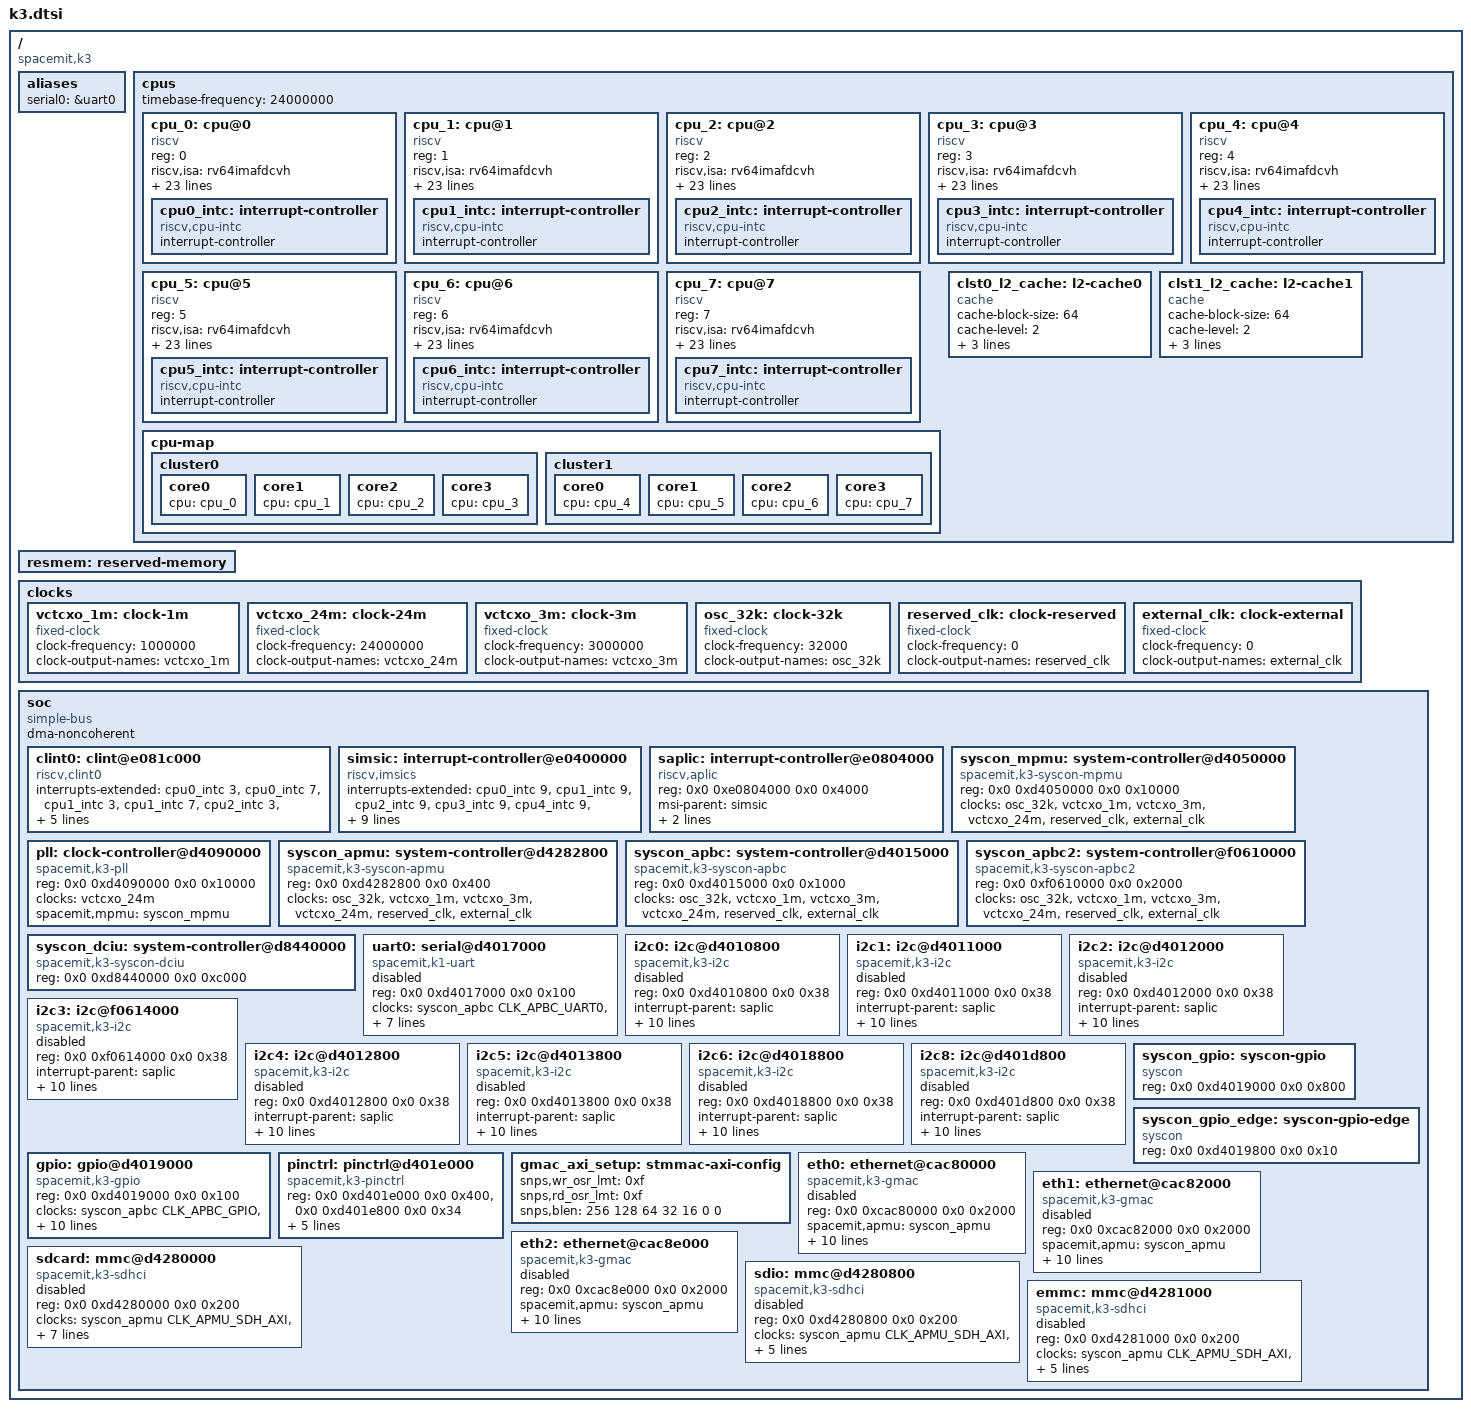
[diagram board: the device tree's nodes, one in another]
// SPDX-License-Identifier: (GPL-2.0 OR MIT)
/* Copyright (c) 2025 Spacemit, Inc */

/dts-v1/;

#include <dt-bindings/clock/spacemit,k3-syscon.h>
#include <dt-bindings/interrupt-controller/irq.h>

/ {
	compatible = "spacemit,k3";
	#address-cells = <2>;
	#size-cells = <2>;

	aliases {
		serial0 = &uart0;
	};

	cpus: cpus {
		#address-cells = <1>;
		#size-cells = <0>;
		timebase-frequency = <24000000>;

		cpu_0: cpu@0 {
			device_type = "cpu";
			reg = <0>;
			status = "okay";
			compatible = "riscv";
			riscv,isa = "rv64imafdcvh";
			riscv,isa-base = "rv64i";
			riscv,isa-extensions = "i", "m", "a", "f", "d", "c", "v", "h",
					       "smaia", "smstateen", "ssaia", "sscofpmf",
					       "ssnpm", "sstc", "svade", "svinval",
					       "svnapot", "svpbmt", "zawrs", "zba", "zbb",
					       "zbc", "zbs", "zca", "zcb", "zcd", "zcmop",
					       "zfa", "zfbfmin", "zfh", "zfhmin", "zicbom", "zicbop",
					       "zicboz", "zicntr", "zicond", "zicsr",
					       "zifencei", "zihintntl", "zihintpause",
					       "zihpm", "zimop", "zkt", "zvbb", "zvbc",
					       "zvfbfmin", "zvfbfwma", "zvfh", "zvfhmin",
					       "zvkb", "zvkg", "zvkn", "zvknc", "zvkned",
					       "zvkng", "zvknha", "zvknhb", "zvks",
					       "zvksc", "zvksed", "zvksg", "zvksh", "zvkt";
			riscv,cbom-block-size = <64>;
			riscv,cboz-block-size = <64>;
			riscv,cbop-block-size = <64>;
			i-cache-block-size = <64>;
			i-cache-size = <65536>;
			i-cache-sets = <256>;
			d-cache-block-size = <64>;
			d-cache-size = <65536>;
			d-cache-sets = <256>;
			next-level-cache = <&clst0_l2_cache>;
			mmu-type = "riscv,sv39";
			cpu0_intc: interrupt-controller {
				#interrupt-cells = <1>;
				compatible = "riscv,cpu-intc";
				interrupt-controller;
			};
		};

		cpu_1: cpu@1 {
			device_type = "cpu";
			reg = <1>;
			status = "okay";
			compatible = "riscv";
			riscv,isa = "rv64imafdcvh";
			riscv,isa-base = "rv64i";
			riscv,isa-extensions = "i", "m", "a", "f", "d", "c", "v", "h",
					       "smaia", "smstateen", "ssaia", "sscofpmf",
					       "ssnpm", "sstc", "svade", "svinval",
					       "svnapot", "svpbmt", "zawrs", "zba", "zbb",
					       "zbc", "zbs", "zca", "zcb", "zcd", "zcmop",
					       "zfa", "zfbfmin", "zfh", "zfhmin", "zicbom", "zicbop",
					       "zicboz", "zicntr", "zicond", "zicsr",
					       "zifencei", "zihintntl", "zihintpause",
					       "zihpm", "zimop", "zkt", "zvbb", "zvbc",
					       "zvfbfmin", "zvfbfwma", "zvfh", "zvfhmin",
					       "zvkb", "zvkg", "zvkn", "zvknc", "zvkned",
					       "zvkng", "zvknha", "zvknhb", "zvks",
					       "zvksc", "zvksed", "zvksg", "zvksh", "zvkt";
			riscv,cbom-block-size = <64>;
			riscv,cboz-block-size = <64>;
			riscv,cbop-block-size = <64>;
			i-cache-block-size = <64>;
			i-cache-size = <65536>;
			i-cache-sets = <256>;
			d-cache-block-size = <64>;
			d-cache-size = <65536>;
			d-cache-sets = <256>;
			next-level-cache = <&clst0_l2_cache>;
			mmu-type = "riscv,sv39";
			cpu1_intc: interrupt-controller {
				#interrupt-cells = <1>;
				compatible = "riscv,cpu-intc";
				interrupt-controller;
			};
		};

		cpu_2: cpu@2 {
			device_type = "cpu";
			reg = <2>;
			status = "okay";
			compatible = "riscv";
			riscv,isa = "rv64imafdcvh";
			riscv,isa-base = "rv64i";
			riscv,isa-extensions = "i", "m", "a", "f", "d", "c", "v", "h",
					       "smaia", "smstateen", "ssaia", "sscofpmf",
					       "ssnpm", "sstc", "svade", "svinval",
					       "svnapot", "svpbmt", "zawrs", "zba", "zbb",
					       "zbc", "zbs", "zca", "zcb", "zcd", "zcmop",
					       "zfa", "zfbfmin", "zfh", "zfhmin", "zicbom", "zicbop",
					       "zicboz", "zicntr", "zicond", "zicsr",
					       "zifencei", "zihintntl", "zihintpause",
					       "zihpm", "zimop", "zkt", "zvbb", "zvbc",
					       "zvfbfmin", "zvfbfwma", "zvfh", "zvfhmin",
					       "zvkb", "zvkg", "zvkn", "zvknc", "zvkned",
					       "zvkng", "zvknha", "zvknhb", "zvks",
					       "zvksc", "zvksed", "zvksg", "zvksh", "zvkt";
			riscv,cbom-block-size = <64>;
			riscv,cboz-block-size = <64>;
			riscv,cbop-block-size = <64>;
			i-cache-block-size = <64>;
			i-cache-size = <65536>;
			i-cache-sets = <256>;
			d-cache-block-size = <64>;
			d-cache-size = <65536>;
			d-cache-sets = <256>;
			next-level-cache = <&clst0_l2_cache>;
			mmu-type = "riscv,sv39";
			cpu2_intc: interrupt-controller {
				#interrupt-cells = <1>;
				compatible = "riscv,cpu-intc";
				interrupt-controller;
			};
		};

		cpu_3: cpu@3 {
			device_type = "cpu";
			reg = <3>;
			status = "okay";
			compatible = "riscv";
			riscv,isa = "rv64imafdcvh";
			riscv,isa-base = "rv64i";
			riscv,isa-extensions = "i", "m", "a", "f", "d", "c", "v", "h",
					       "smaia", "smstateen", "ssaia", "sscofpmf",
					       "ssnpm", "sstc", "svade", "svinval",
					       "svnapot", "svpbmt", "zawrs", "zba", "zbb",
					       "zbc", "zbs", "zca", "zcb", "zcd", "zcmop",
					       "zfa", "zfbfmin", "zfh", "zfhmin", "zicbom", "zicbop",
					       "zicboz", "zicntr", "zicond", "zicsr",
					       "zifencei", "zihintntl", "zihintpause",
					       "zihpm", "zimop", "zkt", "zvbb", "zvbc",
					       "zvfbfmin", "zvfbfwma", "zvfh", "zvfhmin",
					       "zvkb", "zvkg", "zvkn", "zvknc", "zvkned",
					       "zvkng", "zvknha", "zvknhb", "zvks",
					       "zvksc", "zvksed", "zvksg", "zvksh", "zvkt";
			riscv,cbom-block-size = <64>;
			riscv,cboz-block-size = <64>;
			riscv,cbop-block-size = <64>;
			i-cache-block-size = <64>;
			i-cache-size = <65536>;
			i-cache-sets = <256>;
			d-cache-block-size = <64>;
			d-cache-size = <65536>;
			d-cache-sets = <256>;
			next-level-cache = <&clst0_l2_cache>;
			mmu-type = "riscv,sv39";
			cpu3_intc: interrupt-controller {
				#interrupt-cells = <1>;
				compatible = "riscv,cpu-intc";
				interrupt-controller;
			};
		};

		cpu_4: cpu@4 {
			device_type = "cpu";
			reg = <4>;
			status = "okay";
			compatible = "riscv";
			riscv,isa = "rv64imafdcvh";
			riscv,isa-base = "rv64i";
			riscv,isa-extensions = "i", "m", "a", "f", "d", "c", "v", "h",
					       "smaia", "smstateen", "ssaia", "sscofpmf",
					       "ssnpm", "sstc", "svade", "svinval",
					       "svnapot", "svpbmt", "zawrs", "zba", "zbb",
					       "zbc", "zbs", "zca", "zcb", "zcd", "zcmop",
					       "zfa", "zfbfmin", "zfh", "zfhmin", "zicbom", "zicbop",
					       "zicboz", "zicntr", "zicond", "zicsr",
					       "zifencei", "zihintntl", "zihintpause",
					       "zihpm", "zimop", "zkt", "zvbb", "zvbc",
					       "zvfbfmin", "zvfbfwma", "zvfh", "zvfhmin",
					       "zvkb", "zvkg", "zvkn", "zvknc", "zvkned",
					       "zvkng", "zvknha", "zvknhb", "zvks",
					       "zvksc", "zvksed", "zvksg", "zvksh", "zvkt";
			riscv,cbom-block-size = <64>;
			riscv,cboz-block-size = <64>;
			riscv,cbop-block-size = <64>;
			i-cache-block-size = <64>;
			i-cache-size = <65536>;
			i-cache-sets = <256>;
			d-cache-block-size = <64>;
			d-cache-size = <65536>;
			d-cache-sets = <256>;
			next-level-cache = <&clst1_l2_cache>;
			mmu-type = "riscv,sv39";
			cpu4_intc: interrupt-controller {
				#interrupt-cells = <1>;
				compatible = "riscv,cpu-intc";
				interrupt-controller;
			};
		};

		cpu_5: cpu@5 {
			device_type = "cpu";
			reg = <5>;
			status = "okay";
			compatible = "riscv";
			riscv,isa = "rv64imafdcvh";
			riscv,isa-base = "rv64i";
			riscv,isa-extensions = "i", "m", "a", "f", "d", "c", "v", "h",
					       "smaia", "smstateen", "ssaia", "sscofpmf",
					       "ssnpm", "sstc", "svade", "svinval",
					       "svnapot", "svpbmt", "zawrs", "zba", "zbb",
					       "zbc", "zbs", "zca", "zcb", "zcd", "zcmop",
					       "zfa", "zfbfmin", "zfh", "zfhmin", "zicbom", "zicbop",
					       "zicboz", "zicntr", "zicond", "zicsr",
					       "zifencei", "zihintntl", "zihintpause",
					       "zihpm", "zimop", "zkt", "zvbb", "zvbc",
					       "zvfbfmin", "zvfbfwma", "zvfh", "zvfhmin",
					       "zvkb", "zvkg", "zvkn", "zvknc", "zvkned",
					       "zvkng", "zvknha", "zvknhb", "zvks",
					       "zvksc", "zvksed", "zvksg", "zvksh", "zvkt";
			riscv,cbom-block-size = <64>;
			riscv,cboz-block-size = <64>;
			riscv,cbop-block-size = <64>;
			i-cache-block-size = <64>;
			i-cache-size = <65536>;
			i-cache-sets = <256>;
			d-cache-block-size = <64>;
			d-cache-size = <65536>;
			d-cache-sets = <256>;
			next-level-cache = <&clst1_l2_cache>;
			mmu-type = "riscv,sv39";
			cpu5_intc: interrupt-controller {
				#interrupt-cells = <1>;
				compatible = "riscv,cpu-intc";
				interrupt-controller;
			};
		};

		cpu_6: cpu@6 {
			device_type = "cpu";
			reg = <6>;
			status = "okay";
			compatible = "riscv";
			riscv,isa = "rv64imafdcvh";
			riscv,isa-base = "rv64i";
			riscv,isa-extensions = "i", "m", "a", "f", "d", "c", "v", "h",
					       "smaia", "smstateen", "ssaia", "sscofpmf",
					       "ssnpm", "sstc", "svade", "svinval",
					       "svnapot", "svpbmt", "zawrs", "zba", "zbb",
					       "zbc", "zbs", "zca", "zcb", "zcd", "zcmop",
					       "zfa", "zfbfmin", "zfh", "zfhmin", "zicbom", "zicbop",
					       "zicboz", "zicntr", "zicond", "zicsr",
					       "zifencei", "zihintntl", "zihintpause",
					       "zihpm", "zimop", "zkt", "zvbb", "zvbc",
					       "zvfbfmin", "zvfbfwma", "zvfh", "zvfhmin",
					       "zvkb", "zvkg", "zvkn", "zvknc", "zvkned",
					       "zvkng", "zvknha", "zvknhb", "zvks",
					       "zvksc", "zvksed", "zvksg", "zvksh", "zvkt";
			riscv,cbom-block-size = <64>;
			riscv,cboz-block-size = <64>;
			riscv,cbop-block-size = <64>;
			i-cache-block-size = <64>;
			i-cache-size = <65536>;
			i-cache-sets = <256>;
			d-cache-block-size = <64>;
			d-cache-size = <65536>;
			d-cache-sets = <256>;
			next-level-cache = <&clst1_l2_cache>;
			mmu-type = "riscv,sv39";
			cpu6_intc: interrupt-controller {
				#interrupt-cells = <1>;
				compatible = "riscv,cpu-intc";
				interrupt-controller;
			};
		};

		cpu_7: cpu@7 {
			device_type = "cpu";
			reg = <7>;
			status = "okay";
			compatible = "riscv";
			riscv,isa = "rv64imafdcvh";
			riscv,isa-base = "rv64i";
			riscv,isa-extensions = "i", "m", "a", "f", "d", "c", "v", "h",
					       "smaia", "smstateen", "ssaia", "sscofpmf",
					       "ssnpm", "sstc", "svade", "svinval",
					       "svnapot", "svpbmt", "zawrs", "zba", "zbb",
					       "zbc", "zbs", "zca", "zcb", "zcd", "zcmop",
					       "zfa", "zfbfmin", "zfh", "zfhmin", "zicbom", "zicbop",
					       "zicboz", "zicntr", "zicond", "zicsr",
					       "zifencei", "zihintntl", "zihintpause",
					       "zihpm", "zimop", "zkt", "zvbb", "zvbc",
					       "zvfbfmin", "zvfbfwma", "zvfh", "zvfhmin",
					       "zvkb", "zvkg", "zvkn", "zvknc", "zvkned",
					       "zvkng", "zvknha", "zvknhb", "zvks",
					       "zvksc", "zvksed", "zvksg", "zvksh", "zvkt";
			riscv,cbom-block-size = <64>;
			riscv,cboz-block-size = <64>;
			riscv,cbop-block-size = <64>;
			i-cache-block-size = <64>;
			i-cache-size = <65536>;
			i-cache-sets = <256>;
			d-cache-block-size = <64>;
			d-cache-size = <65536>;
			d-cache-sets = <256>;
			next-level-cache = <&clst1_l2_cache>;
			mmu-type = "riscv,sv39";
			cpu7_intc: interrupt-controller {
				#interrupt-cells = <1>;
				compatible = "riscv,cpu-intc";
				interrupt-controller;
			};
		};

		cpu-map {
			cluster0 {
				core0 {
					cpu = <&cpu_0>;
				};

				core1 {
					cpu = <&cpu_1>;
				};

				core2 {
					cpu = <&cpu_2>;
				};

				core3 {
					cpu = <&cpu_3>;
				};
			};
			cluster1 {
				core0 {
					cpu = <&cpu_4>;
				};

				core1 {
					cpu = <&cpu_5>;
				};

				core2 {
					cpu = <&cpu_6>;
				};

				core3 {
					cpu = <&cpu_7>;
				};
			};
		};

		clst0_l2_cache: l2-cache0 {
			compatible = "cache";
			cache-block-size = <64>;
			cache-level = <2>;
			cache-size = <4194304>;
			cache-sets = <4096>;
			cache-unified;
		};

		clst1_l2_cache: l2-cache1 {
			compatible = "cache";
			cache-block-size = <64>;
			cache-level = <2>;
			cache-size = <4194304>;
			cache-sets = <4096>;
			cache-unified;
		};
	};

	resmem: reserved-memory {
		#address-cells = <2>;
		#size-cells = <2>;
		ranges;
	};

	clocks {
		vctcxo_1m: clock-1m {
			compatible = "fixed-clock";
			clock-frequency = <1000000>;
			clock-output-names = "vctcxo_1m";
			#clock-cells = <0>;
		};

		vctcxo_24m: clock-24m {
			compatible = "fixed-clock";
			clock-frequency = <24000000>;
			clock-output-names = "vctcxo_24m";
			#clock-cells = <0>;
		};

		vctcxo_3m: clock-3m {
			compatible = "fixed-clock";
			clock-frequency = <3000000>;
			clock-output-names = "vctcxo_3m";
			#clock-cells = <0>;
		};

		osc_32k: clock-32k {
			compatible = "fixed-clock";
			clock-frequency = <32000>;
			clock-output-names = "osc_32k";
			#clock-cells = <0>;
		};

		reserved_clk: clock-reserved {
			compatible = "fixed-clock";
			clock-frequency = <0>;
			clock-output-names = "reserved_clk";
			#clock-cells = <0>;
		};

		external_clk: clock-external {
			compatible = "fixed-clock";
			clock-frequency = <0>;
			clock-output-names = "external_clk";
			#clock-cells = <0>;
		};
	};

	soc: soc {
		#address-cells = <2>;
		#size-cells = <2>;
		compatible = "simple-bus";
		dma-noncoherent;
		ranges;

		clint0: clint@e081c000 {
			compatible = "riscv,clint0";
			interrupts-extended = <
				&cpu0_intc  3 &cpu0_intc  7
				&cpu1_intc  3 &cpu1_intc  7
				&cpu2_intc  3 &cpu2_intc  7
				&cpu3_intc  3 &cpu3_intc  7
				&cpu4_intc  3 &cpu4_intc  7
				&cpu5_intc  3 &cpu5_intc  7
				&cpu6_intc  3 &cpu6_intc  7
				&cpu7_intc  3 &cpu7_intc  7>;
			reg = <0x0 0xe081c000 0x0 0x0004000>;
		};

		simsic: interrupt-controller@e0400000 {
			compatible = "riscv,imsics";
			interrupts-extended = <
				&cpu0_intc 9 &cpu1_intc 9
				&cpu2_intc 9 &cpu3_intc 9
				&cpu4_intc 9 &cpu5_intc 9
				&cpu6_intc 9 &cpu7_intc 9>;

			reg = <0x0 0xe0400000 0x0 0x40000
				0x0 0xe0440000 0x0 0x40000
				0x0 0xe0480000 0x0 0x40000
				0x0 0xe04c0000 0x0 0x40000
				0x0 0xe0500000 0x0 0x40000
				0x0 0xe0540000 0x0 0x40000
				0x0 0xe0580000 0x0 0x40000
				0x0 0xe05c0000 0x0 0x40000>;
			interrupt-controller;
			#interrupt-cells = <0>;
			#msi-cells = <0>;
			msi-controller;
			/* Number of interrupt identities: 511 */
			riscv,num-ids = <511>;
			/* Number of guest interrupt identities: 511 */
			riscv,num-guest-ids = <511>;
			/* Number of HART index bits: 4 (2^4 = 16 harts) */
			riscv,hart-index-bits = <4>;
			riscv,guest-index-bits = <6>;
			status = "okay";
		};

		saplic: interrupt-controller@e0804000 {
			compatible = "riscv,aplic";
			/* aplic config */
			reg = <0x0 0xe0804000 0x0 0x4000>;
			msi-parent = <&simsic>;
			#interrupt-cells = <2>;
			interrupt-controller;
			/* the number of wired interrupt sources:512 */
			riscv,num-sources = <512>;
			status = "okay";
		};

		syscon_mpmu: system-controller@d4050000 {
			compatible = "spacemit,k3-syscon-mpmu", "syscon";
			reg = <0x0 0xd4050000 0x0 0x10000>;
			clocks = <&osc_32k>, <&vctcxo_1m>, <&vctcxo_3m>,
				 <&vctcxo_24m>, <&reserved_clk>, <&external_clk>;
			clock-names = "osc_32k", "vctcxo_1m", "vctcxo_3m", "vctcxo_24m",
				      "reserved_clk", "external_clk";
			#clock-cells = <1>;
			#reset-cells = <1>;
		};

		pll: clock-controller@d4090000 {
			compatible = "spacemit,k3-pll";
			reg = <0x0 0xd4090000 0x0 0x10000>;
			clocks = <&vctcxo_24m>;
			spacemit,mpmu = <&syscon_mpmu>;
			#clock-cells = <1>;
		};

		syscon_apmu: system-controller@d4282800 {
			compatible = "spacemit,k3-syscon-apmu", "syscon";
			reg = <0x0 0xd4282800 0x0 0x400>;
			clocks = <&osc_32k>, <&vctcxo_1m>, <&vctcxo_3m>, <&vctcxo_24m>,
				 <&reserved_clk>, <&external_clk>;
			clock-names = "osc_32k", "vctcxo_1m", "vctcxo_3m", "vctcxo_24m",
				      "reserved_clk", "external_clk";
			#clock-cells = <1>;
			#power-domain-cells = <1>;
			#reset-cells = <1>;
		};

		syscon_apbc: system-controller@d4015000 {
			compatible = "spacemit,k3-syscon-apbc", "syscon";
			reg = <0x0 0xd4015000 0x0 0x1000>;
			clocks = <&osc_32k>, <&vctcxo_1m>, <&vctcxo_3m>, <&vctcxo_24m>,
				 <&reserved_clk>, <&external_clk>;
			clock-names = "osc_32k", "vctcxo_1m", "vctcxo_3m", "vctcxo_24m",
				      "reserved_clk", "external_clk";
			#clock-cells = <1>;
			#reset-cells = <1>;
		};

		syscon_apbc2: system-controller@f0610000 {
			compatible = "spacemit,k3-syscon-apbc2", "syscon";
			reg = <0x0 0xf0610000 0x0 0x2000>;
			clocks = <&osc_32k>, <&vctcxo_1m>, <&vctcxo_3m>, <&vctcxo_24m>,
				 <&reserved_clk>, <&external_clk>;
			clock-names = "osc_32k", "vctcxo_1m", "vctcxo_3m", "vctcxo_24m",
				      "reserved_clk", "external_clk";
			#clock-cells = <1>;
			#reset-cells = <1>;
		};

		syscon_dciu: system-controller@d8440000 {
			compatible = "spacemit,k3-syscon-dciu", "syscon";
			reg = <0x0 0xd8440000 0x0 0xc000>;
			#clock-cells = <1>;
			#reset-cells = <1>;
		};

		uart0: serial@d4017000 {
			compatible = "spacemit,k1-uart",
				     "intel,xscale-uart";
			reg = <0x0 0xd4017000 0x0 0x100>;
			clocks = <&syscon_apbc CLK_APBC_UART0>,
				 <&syscon_apbc CLK_APBC_UART0_BUS>,
				 <&syscon_mpmu CLK_MPMU_SLOW_UART>;
			clock-names = "core", "bus", "gate";
			resets = <&syscon_apbc RESET_APBC_UART0>;
			reg-shift = <2>;
			reg-io-width = <4>;
			interrupt-parent = <&saplic>;
			interrupts = <42 IRQ_TYPE_LEVEL_HIGH>;
			status = "disabled";
		};

		i2c0: i2c@d4010800 {
			compatible = "spacemit,k3-i2c",
				     "spacemit,k1-i2c";
			reg = <0x0 0xd4010800 0x0 0x38>;
			#address-cells = <1>;
			#size-cells = <0>;
			interrupt-parent = <&saplic>;
			interrupts = <36 IRQ_TYPE_LEVEL_HIGH>;
			clocks = <&syscon_apbc CLK_APBC_TWSI0>,
				 <&syscon_apbc CLK_APBC_TWSI0_BUS>;
			clock-names = "func", "bus";
			resets = <&syscon_apbc RESET_APBC_TWSI0>;

			spacemit,adapter-id = <0>;
			spacemit,i2c-master-code = /bits/ 8 <0x0e>;
			spacemit,i2c-clk-rate = <32000000>;
			spacemit,i2c-lcr = <0x82c469f>;
			spacemit,i2c-wcr = <0x142a>;
			/* apb clock: 26MHz or 52MHz */
			spacemit,apb_clock = <52000000>;

			status = "disabled";
		};

		i2c1: i2c@d4011000 {
			compatible = "spacemit,k3-i2c",
				     "spacemit,k1-i2c";
			reg = <0x0 0xd4011000 0x0 0x38>;
			#address-cells = <1>;
			#size-cells = <0>;
			interrupt-parent = <&saplic>;
			interrupts = <37 IRQ_TYPE_LEVEL_HIGH>;
			clocks = <&syscon_apbc CLK_APBC_TWSI1>,
				 <&syscon_apbc CLK_APBC_TWSI1_BUS>;
			clock-names = "func", "bus";
			resets = <&syscon_apbc RESET_APBC_TWSI1>;

			spacemit,adapter-id = <1>;
			spacemit,i2c-master-code = /bits/ 8 <0x0e>;
			spacemit,i2c-clk-rate = <32000000>;
			spacemit,i2c-lcr = <0x82c469f>;
			spacemit,i2c-wcr = <0x142a>;
			/* apb clock: 26MHz or 52MHz */
			spacemit,apb_clock = <52000000>;

			status = "disabled";
		};

		i2c2: i2c@d4012000 {
			compatible = "spacemit,k3-i2c",
				     "spacemit,k1-i2c";
			reg = <0x0 0xd4012000 0x0 0x38>;
			#address-cells = <1>;
			#size-cells = <0>;
			interrupt-parent = <&saplic>;
			interrupts = <38 IRQ_TYPE_LEVEL_HIGH>;
			clocks = <&syscon_apbc CLK_APBC_TWSI2>,
				 <&syscon_apbc CLK_APBC_TWSI2_BUS>;
			clock-names = "func", "bus";
			resets = <&syscon_apbc RESET_APBC_TWSI2>;

			spacemit,adapter-id = <2>;
			spacemit,i2c-master-code = /bits/ 8 <0x0e>;
			spacemit,i2c-clk-rate = <32000000>;
			spacemit,i2c-lcr = <0x82c469f>;
			spacemit,i2c-wcr = <0x142a>;
			/* apb clock: 26MHz or 52MHz */
			spacemit,apb_clock = <52000000>;

			status = "disabled";
		};

		i2c3: i2c@f0614000 {
			compatible = "spacemit,k3-i2c",
				     "spacemit,k1-i2c";
			reg = <0x0 0xf0614000 0x0 0x38>;
			#address-cells = <1>;
			#size-cells = <0>;
			interrupt-parent = <&saplic>;
			interrupts = <39 IRQ_TYPE_LEVEL_HIGH>;
			clocks = <&syscon_apbc2 CLK_APBC2_SEC_TWSI3>,
				 <&syscon_apbc2 CLK_APBC2_SEC_TWSI3_BUS>;
			clock-names = "func", "bus";
			resets = <&syscon_apbc2 RESET_APBC2_SEC_TWSI3>;

			spacemit,adapter-id = <3>;
			spacemit,i2c-master-code = /bits/ 8 <0x0e>;
			spacemit,i2c-clk-rate = <32000000>;
			spacemit,i2c-lcr = <0x82c469f>;
			spacemit,i2c-wcr = <0x142a>;
			/* apb clock: 26MHz or 52MHz */
			spacemit,apb_clock = <52000000>;

			status = "disabled";
		};

		i2c4: i2c@d4012800 {
			compatible = "spacemit,k3-i2c",
				     "spacemit,k1-i2c";
			reg = <0x0 0xd4012800 0x0 0x38>;
			#address-cells = <1>;
			#size-cells = <0>;
			interrupt-parent = <&saplic>;
			interrupts = <40 IRQ_TYPE_LEVEL_HIGH>;
			clocks = <&syscon_apbc CLK_APBC_TWSI4>,
				 <&syscon_apbc CLK_APBC_TWSI4_BUS>;
			clock-names = "func", "bus";
			resets = <&syscon_apbc RESET_APBC_TWSI4>;

			spacemit,adapter-id = <4>;
			spacemit,i2c-master-code = /bits/ 8 <0x0e>;
			spacemit,i2c-clk-rate = <32000000>;
			spacemit,i2c-lcr = <0x82c469f>;
			spacemit,i2c-wcr = <0x142a>;
			/* apb clock: 26MHz or 52MHz */
			spacemit,apb_clock = <52000000>;

			status = "disabled";
		};

		i2c5: i2c@d4013800 {
			compatible = "spacemit,k3-i2c",
				     "spacemit,k1-i2c";
			reg = <0x0 0xd4013800 0x0 0x38>;
			#address-cells = <1>;
			#size-cells = <0>;
			interrupt-parent = <&saplic>;
			interrupts = <41 IRQ_TYPE_LEVEL_HIGH>;
			clocks = <&syscon_apbc CLK_APBC_TWSI5>,
				 <&syscon_apbc CLK_APBC_TWSI5_BUS>;
			clock-names = "func", "bus";
			resets = <&syscon_apbc RESET_APBC_TWSI5>;

			spacemit,adapter-id = <5>;
			spacemit,i2c-master-code = /bits/ 8 <0x0e>;
			spacemit,i2c-clk-rate = <32000000>;
			spacemit,i2c-lcr = <0x82c469f>;
			spacemit,i2c-wcr = <0x142a>;
			/* apb clock: 26MHz or 52MHz */
			spacemit,apb_clock = <52000000>;

			status = "disabled";
		};

		i2c6: i2c@d4018800 {
			compatible = "spacemit,k3-i2c",
				     "spacemit,k1-i2c";
			reg = <0x0 0xd4018800 0x0 0x38>;
			#address-cells = <1>;
			#size-cells = <0>;
			interrupt-parent = <&saplic>;
			interrupts = <70 IRQ_TYPE_LEVEL_HIGH>;
			clocks = <&syscon_apbc CLK_APBC_TWSI6>,
				 <&syscon_apbc CLK_APBC_TWSI6_BUS>;
			clock-names = "func", "bus";
			resets = <&syscon_apbc RESET_APBC_TWSI6>;

			spacemit,adapter-id = <6>;
			spacemit,i2c-master-code = /bits/ 8 <0x0e>;
			spacemit,i2c-clk-rate = <32000000>;
			spacemit,i2c-lcr = <0x82c469f>;
			spacemit,i2c-wcr = <0x142a>;
			/* apb clock: 26MHz or 52MHz */
			spacemit,apb_clock = <52000000>;

			status = "disabled";
		};

		i2c8: i2c@d401d800 {
			compatible = "spacemit,k3-i2c",
				     "spacemit,k1-i2c";
			reg = <0x0 0xd401d800 0x0 0x38>;
			#address-cells = <1>;
			#size-cells = <0>;
			interrupt-parent = <&saplic>;
			interrupts = <19 IRQ_TYPE_LEVEL_HIGH>;
			clocks = <&syscon_apbc CLK_APBC_TWSI8>,
				 <&syscon_apbc CLK_APBC_TWSI8_BUS>;
			clock-names = "func", "bus";
			resets = <&syscon_apbc RESET_APBC_TWSI8>;

			spacemit,adapter-id = <8>;
			spacemit,i2c-master-code = /bits/ 8 <0x0e>;
			spacemit,i2c-clk-rate = <32000000>;
			spacemit,i2c-lcr = <0x82c469f>;
			spacemit,i2c-wcr = <0x142a>;
			/* apb clock: 26MHz or 52MHz */
			spacemit,apb_clock = <52000000>;

			status = "disabled";
		};

		syscon_gpio: syscon-gpio{
			compatible = "syscon";
			reg = <0x0 0xd4019000 0x0 0x800>;
		};

		syscon_gpio_edge: syscon-gpio-edge{
			compatible = "syscon";
			reg = <0x0 0xd4019800 0x0 0x10>;
		};

		gpio: gpio@d4019000 {
			compatible = "spacemit,k3-gpio";
			reg = <0x0 0xd4019000 0x0 0x100>;
			clocks = <&syscon_apbc CLK_APBC_GPIO>,
				 <&syscon_apbc CLK_APBC_GPIO_BUS>;
			clock-names = "core", "bus";
			gpio-controller;
			#gpio-cells = <3>;
			interrupts = <58 IRQ_TYPE_LEVEL_HIGH>;
			interrupt-parent = <&saplic>;
			interrupt-controller;
			#interrupt-cells = <3>;
			syscon = <&syscon_gpio>;
			syscon-edge = <&syscon_gpio_edge>;
			gpio-ranges = <&pinctrl 0 0 0 32>,
				      <&pinctrl 1 0 32 32>,
				      <&pinctrl 2 0 64 32>,
				      <&pinctrl 3 0 96 32>;
		};

		pinctrl: pinctrl@d401e000 {
			compatible = "spacemit,k3-pinctrl";
			reg = <0x0 0xd401e000 0x0 0x400>,
			      <0x0 0xd401e800 0x0 0x34>;
			clocks = <&syscon_apbc CLK_APBC_AIB>,
				 <&syscon_apbc CLK_APBC_AIB_BUS>;
			clock-names = "func", "bus";
			syscon = <&syscon_gpio>;
			syscon-edge = <&syscon_gpio_edge>;
			spacemit,apbc = <&syscon_apbc 0x50>;
		};

		gmac_axi_setup: stmmac-axi-config {
			snps,wr_osr_lmt = <0xf>;
			snps,rd_osr_lmt = <0xf>;
			/* max axi burst len is 256 */
			snps,blen = <256 128 64 32 16 0 0>;
		};

		eth0: ethernet@cac80000 {
			compatible = "spacemit,k3-gmac", "snps,dwmac-5.10a";
			reg = <0x0 0xcac80000 0x0 0x2000>;
			spacemit,apmu = <&syscon_apmu>;
			spacemit,ctrl-offset = <0x3e4>;
			spacemit,dline-offset = <0x3e8>;
			clocks = <&syscon_apmu CLK_APMU_EMAC0_BUS>,
				 <&syscon_apmu CLK_APMU_EMAC0_1588>;
			clock-names = "stmmaceth", "ptp_ref";
			resets = <&syscon_apmu RESET_APMU_EMAC0>;
			reset-names = "stmmaceth";
			interrupt-parent = <&saplic>;
			interrupts = <131 IRQ_TYPE_LEVEL_HIGH>, <276 IRQ_TYPE_LEVEL_HIGH>;
			interrupt-names = "macirq", "eth_wake_irq";
			mac-address = [00 00 00 00 00 00];
			snps,axi-config = <&gmac_axi_setup>;
			status = "disabled";
		};

		eth1: ethernet@cac82000 {
			compatible = "spacemit,k3-gmac", "snps,dwmac-5.10a";
			reg = <0x0 0xcac82000 0x0 0x2000>;
			spacemit,apmu = <&syscon_apmu>;
			spacemit,ctrl-offset = <0x3ec>;
			spacemit,dline-offset = <0x3f0>;
			clocks = <&syscon_apmu CLK_APMU_EMAC1_BUS>,
				 <&syscon_apmu CLK_APMU_EMAC1_1588>;
			clock-names = "stmmaceth", "ptp_ref";
			resets = <&syscon_apmu RESET_APMU_EMAC1>;
			reset-names = "stmmaceth";
			interrupt-parent = <&saplic>;
			interrupts = <133 IRQ_TYPE_LEVEL_HIGH>, <277 IRQ_TYPE_LEVEL_HIGH>;
			interrupt-names = "macirq", "eth_wake_irq";
			mac-address = [00 00 00 00 00 00];
			snps,axi-config = <&gmac_axi_setup>;
			status = "disabled";
		};

		eth2: ethernet@cac8e000 {
			compatible = "spacemit,k3-gmac", "snps,dwmac-5.10a";
			reg = <0x0 0xcac8e000 0x0 0x2000>;
			spacemit,apmu = <&syscon_apmu>;
			spacemit,ctrl-offset = <0x248>;
			spacemit,dline-offset = <0x24c>;
			clocks = <&syscon_apmu CLK_APMU_EMAC2_BUS>,
				 <&syscon_apmu CLK_APMU_EMAC2_1588>;
			clock-names = "stmmaceth", "ptp_ref";
			resets = <&syscon_apmu RESET_APMU_EMAC2>;
			reset-names = "stmmaceth";
			interrupt-parent = <&saplic>;
			interrupts = <130 IRQ_TYPE_LEVEL_HIGH>, <278 IRQ_TYPE_LEVEL_HIGH>;
			interrupt-names = "macirq", "eth_wake_irq";
			mac-address = [00 00 00 00 00 00];
			snps,axi-config = <&gmac_axi_setup>;
			status = "disabled";
		};

		sdcard: mmc@d4280000 {
			compatible = "spacemit,k3-sdhci";
			reg = <0x0 0xd4280000 0x0 0x200>;
			clocks = <&syscon_apmu CLK_APMU_SDH_AXI>,
				 <&syscon_apmu CLK_APMU_SDH0>,
				 <&syscon_apbc CLK_APBC_AIB_BUS>,
				 <&syscon_apbc CLK_APBC_AIB>;
			clock-names = "core", "io", "aib-bus", "aib";
			interrupt-parent = <&saplic>;
			interrupts = <99 IRQ_TYPE_LEVEL_HIGH>;
			resets = <&syscon_apmu RESET_APMU_SDH_AXI>,
				 <&syscon_apmu RESET_APMU_SDH0>;
			reset-names = "sdh_axi", "sdh0";
			status = "disabled";
		};

		sdio: mmc@d4280800 {
			compatible = "spacemit,k3-sdhci";
			reg = <0x0 0xd4280800 0x0 0x200>;
			clocks = <&syscon_apmu CLK_APMU_SDH_AXI>,
				 <&syscon_apmu CLK_APMU_SDH1>;
			clock-names = "core", "io";
			interrupt-parent = <&saplic>;
			interrupts = <100 IRQ_TYPE_LEVEL_HIGH>;
			resets = <&syscon_apmu RESET_APMU_SDH_AXI>,
				 <&syscon_apmu RESET_APMU_SDH1>;
			reset-names = "sdh_axi", "sdh1";
			status = "disabled";
		};

		emmc: mmc@d4281000 {
			compatible = "spacemit,k3-sdhci";
			reg = <0x0 0xd4281000 0x0 0x200>;
			clocks = <&syscon_apmu CLK_APMU_SDH_AXI>,
				 <&syscon_apmu CLK_APMU_SDH2>;
			clock-names = "core", "io";
			interrupt-parent = <&saplic>;
			interrupts = <101 IRQ_TYPE_LEVEL_HIGH>;
			resets = <&syscon_apmu RESET_APMU_SDH_AXI>,
				 <&syscon_apmu RESET_APMU_SDH2>;
			reset-names = "sdh_axi", "sdh2";
			status = "disabled";
		};
	};
};

